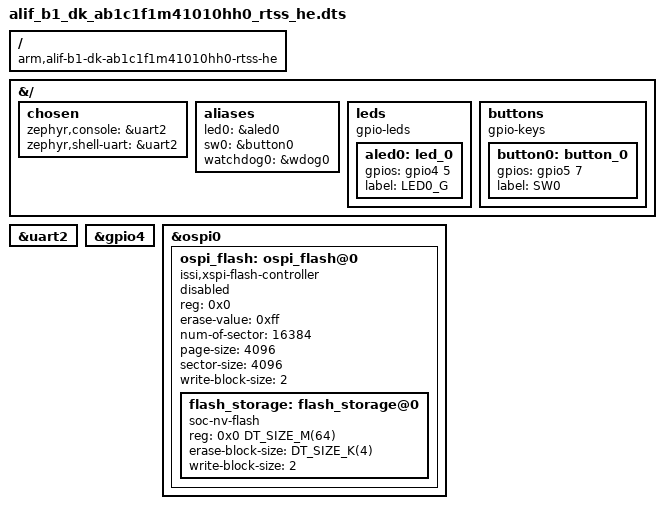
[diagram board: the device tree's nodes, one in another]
/* Copyright (c) 2026 Alif Semiconductor
 *
 * SPDX-License-Identifier: Apache-2.0
 */

/dts-v1/;

#include <alif/balletto/b1/ab1c1f1m41010hh0.dtsi>
#include "../common/balletto-pinctrl.dtsi"

/ {
	compatible = "arm,alif-b1-dk-ab1c1f1m41010hh0-rtss-he";
	#address-cells = <1>;
	#size-cells = <1>;
};

&{/} {
	chosen {
		zephyr,console = &uart2;
		zephyr,shell-uart = &uart2;
	};

	aliases {
		led0 = &aled0;
		sw0 = &button0;
		watchdog0 = &wdog0;
	};

	leds {
		compatible = "gpio-leds";
		aled0: led_0 {
			gpios = <&gpio4 5 0>;
			label = "LED0_G";
		};
	};

	buttons {
		compatible = "gpio-keys";
		button0: button_0 {
			gpios = <&gpio5 7 0>;
			label = "SW0";
		};
	};
};

&uart2 {
	status = "okay";
};

&gpio4 {
	status = "okay";
};

&ospi0 {
	/* External Flash on OSPI */
	ospi_flash: ospi_flash@0 {
		compatible = "issi,xspi-flash-controller";
		reg = <0x0>;
		erase-value = <0xff>;
		num-of-sector = <16384>;
		page-size = <4096>;
		sector-size = <4096>;
		write-block-size = <2>;

		/* Flash Size 64MB */
		#address-cells = <1>;
		#size-cells = <1>;

		flash_storage: flash_storage@0 {
			compatible = "soc-nv-flash";
			reg = <0x0 DT_SIZE_M(64)>;
			erase-block-size = <DT_SIZE_K(4)>;
			write-block-size = <2>;
		};
		status = "disabled";
	};
};
